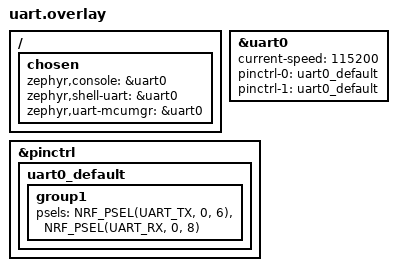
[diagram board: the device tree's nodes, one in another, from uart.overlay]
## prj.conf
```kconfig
CONFIG_CONSOLE=y            # enable console abstraction
CONFIG_SERIAL=y             # serial API (RTT, UART, and USB)
CONFIG_PRINTK=y             # enable printk
CONFIG_LOG=y                # enable logging subsystem
CONFIG_BUILD_OUTPUT_UF2=y   # build UF2 for flashing
CONFIG_DEBUG=y              # debug hooks enabled
```

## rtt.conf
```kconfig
CONFIG_USE_SEGGER_RTT=y
CONFIG_RTT_CONSOLE=y
CONFIG_LOG_BACKEND_RTT=y
CONFIG_UART_CONSOLE=n
CONFIG_UART_INTERRUPT_DRIVEN=n
CONFIG_LOG_BACKEND_UART=n
CONFIG_USB_DEVICE_STACK=n
CONFIG_USB_DEVICE_STACK_NEXT=n
CONFIG_USB_CDC_ACM=n
```

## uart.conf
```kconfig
CONFIG_UART_CONSOLE=y
CONFIG_UART_INTERRUPT_DRIVEN=y
CONFIG_NRFX_UARTE0=y
```

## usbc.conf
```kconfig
CONFIG_USB_CDC_ACM=y
CONFIG_USB_DEVICE_STACK_NEXT=y
```

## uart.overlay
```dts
/ {
    chosen {
        zephyr,console = &uart0;
        zephyr,shell-uart = &uart0;
        zephyr,uart-mcumgr = &uart0;
    };
};

&uart0 {
    status = "okay";
    current-speed = <115200>;
    pinctrl-0 = <&uart0_default>;
    pinctrl-1 = <&uart0_default>;      // duplicate for second entry
    pinctrl-names = "default", "sleep"; // two strings
};

&pinctrl {
    uart0_default: uart0_default {
        group1 {
            psels = <NRF_PSEL(UART_TX, 0, 6)>,
                    <NRF_PSEL(UART_RX, 0, 8)>;
        };
    };
};
```

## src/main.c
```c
#include <zephyr/kernel.h>
#include <zephyr/drivers/gpio.h>

#define LED0_NODE DT_ALIAS(led0)
static const struct gpio_dt_spec led = GPIO_DT_SPEC_GET(LED0_NODE, gpios);

int main(void)
{
    gpio_pin_configure_dt(&led, GPIO_OUTPUT_ACTIVE);

    /* Give USB time to enumerate */
    k_sleep(K_SECONDS(2));

    printk("USB console ready\n");

    while (1) {
        printk("alive\n");
        gpio_pin_toggle_dt(&led);
        k_sleep(K_SECONDS(1));
    }
}
```
